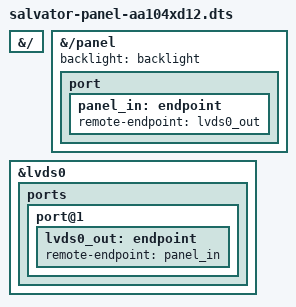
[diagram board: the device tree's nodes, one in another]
// SPDX-License-Identifier: (GPL-2.0+ OR MIT)
/*
 * Device Tree overlay for the AA104XD12 panel connected to LVDS0 on a
 * Salvator-X or Salvator-XS board
 *
 * Copyright 2021 Ideas on Board Oy
 */

/dts-v1/;
/plugin/;

&{/} {
#include "panel-aa104xd12.dtsi"
};

&{/panel} {
	backlight = <&backlight>;

	port {
		panel_in: endpoint {
			remote-endpoint = <&lvds0_out>;
		};
	};
};

&lvds0 {
	status = "okay";

	ports {
		port@1 {
			lvds0_out: endpoint {
				remote-endpoint = <&panel_in>;
			};
		};
	};
};
